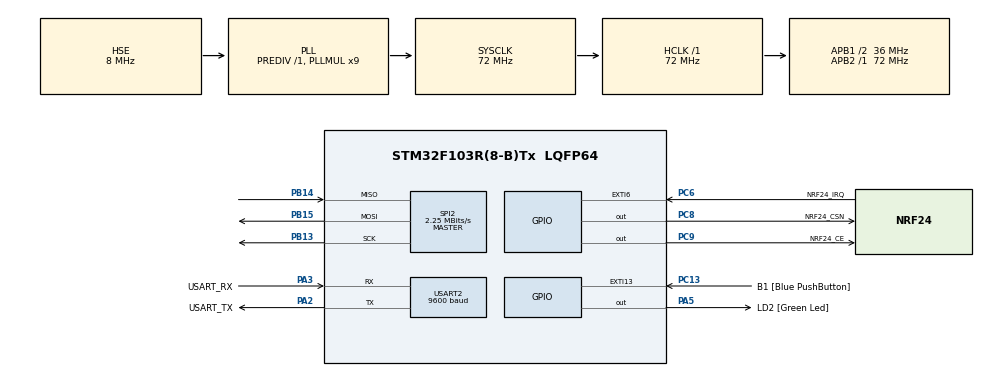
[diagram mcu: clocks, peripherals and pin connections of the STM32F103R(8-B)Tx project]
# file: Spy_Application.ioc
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Mcu.Family=STM32F1
Mcu.Name=STM32F103R(8-B)Tx
Mcu.Package=LQFP64
NVIC.EXTI15_10_IRQn=true\:0\:0\:false\:false\:true\:true\:true
NVIC.EXTI9_5_IRQn=true\:0\:0\:false\:false\:true\:true\:true
NVIC.PriorityGroup=NVIC_PRIORITYGROUP_4
PA13.GPIO_Label=TMS
PA13.Mode=Serial_Wire
PA13.Signal=SYS_JTMS-SWDIO
PA14.GPIO_Label=TCK
PA14.Mode=Serial_Wire
PA14.Signal=SYS_JTCK-SWCLK
PA2.GPIO_Label=USART_TX
PA2.GPIO_Mode=GPIO_MODE_AF_PP
PA2.GPIO_PuPd=GPIO_NOPULL
PA2.GPIO_Speed=GPIO_SPEED_FREQ_LOW
PA2.Mode=Asynchronous
PA2.Signal=USART2_TX
PA3.GPIO_Label=USART_RX
PA3.GPIO_Mode=GPIO_MODE_AF_PP
PA3.GPIO_PuPd=GPIO_NOPULL
PA3.GPIO_Speed=GPIO_SPEED_FREQ_LOW
PA3.Mode=Asynchronous
PA3.Signal=USART2_RX
PA5.GPIO_Label=LD2 [Green Led]
PA5.GPIO_ModeDefaultOutputPP=GPIO_MODE_OUTPUT_PP
PA5.GPIO_PuPd=GPIO_NOPULL
PA5.GPIO_Speed=GPIO_SPEED_FREQ_LOW
PA5.Signal=GPIO_Output
PB13.Mode=Full_Duplex_Master
PB13.Signal=SPI2_SCK
PB14.Mode=Full_Duplex_Master
PB14.Signal=SPI2_MISO
PB15.Mode=Full_Duplex_Master
PB15.Signal=SPI2_MOSI
PB3.GPIO_Label=SWO
PB3.Signal=SYS_JTDO-TRACESWO
PC13-TAMPER-RTC.GPIO_Label=B1 [Blue PushButton]
PC13-TAMPER-RTC.GPIO_PuPd=GPIO_NOPULL
PC13-TAMPER-RTC.Signal=GPXTI13
PC14-OSC32_IN.Mode=LSE-External-Oscillator
PC14-OSC32_IN.Signal=RCC_OSC32_IN
PC15-OSC32_OUT.Mode=LSE-External-Oscillator
PC15-OSC32_OUT.Signal=RCC_OSC32_OUT
PC6.GPIO_Label=NRF24_IRQ
PC6.GPIO_ModeDefaultEXTI=GPIO_MODE_IT_FALLING
PC6.GPIO_PuPd=GPIO_PULLUP
PC6.Signal=GPXTI6
PC8.GPIO_Label=NRF24_CSN
PC8.Signal=GPIO_Output
PC9.GPIO_Label=NRF24_CE
PC9.Signal=GPIO_Output
PD0-OSC_IN.Mode=HSE-External-Clock-Source
PD0-OSC_IN.Signal=RCC_OSC_IN
PD1-OSC_OUT.Mode=HSE-External-Clock-Source
PD1-OSC_OUT.Signal=RCC_OSC_OUT
ProjectManager.HeapSize=0x200
ProjectManager.StackSize=0x400
ProjectManager.TargetToolchain=STM32CubeIDE
RCC.AHBFreq_Value=72000000
RCC.APB1CLKDivider=RCC_HCLK_DIV2
RCC.APB1Freq_Value=36000000
RCC.APB1TimFreq_Value=72000000
RCC.APB2Freq_Value=72000000
RCC.APB2TimFreq_Value=72000000
RCC.HCLKFreq_Value=72000000
RCC.PLLMUL=RCC_PLL_MUL9
RCC.PLLSourceVirtual=RCC_PLLSOURCE_HSE
RCC.RTCClockSelection=RCC_RTCCLKSOURCE_LSE
RCC.SYSCLKFreq_VALUE=72000000
RCC.SYSCLKSource=RCC_SYSCLKSOURCE_PLLCLK
RCC.USBFreq_Value=72000000
SPI2.BaudRatePrescaler=SPI_BAUDRATEPRESCALER_16
SPI2.CalculateBaudRate=2.25 MBits/s
SPI2.Direction=SPI_DIRECTION_2LINES
SPI2.Mode=SPI_MODE_MASTER
SPI2.VirtualType=VM_MASTER
USART2.BaudRate=9600
USART2.VirtualMode=VM_ASYNC
board=NUCLEO-F103RB

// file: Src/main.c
/* USER CODE BEGIN Header */
/**
  ******************************************************************************
  * @file           : main.c
  * @brief          : Main program body
  ******************************************************************************
  * @attention
  *
  * <h2><center>&copy; Copyright (c) 2021 STMicroelectronics.
  * All rights reserved.</center></h2>
  *
  * This software component is licensed by ST under BSD 3-Clause license,
  * the "License"; You may not use this file except in compliance with the
  * License. You may obtain a copy of the License at:
  *                        opensource.org/licenses/BSD-3-Clause
  *
  ******************************************************************************
  */
/* USER CODE END Header */

#include "main.h"
#include "spi.h"
#include "usart.h"
#include "gpio.h"

/* USER CODE BEGIN Includes */
#include "MY_NRF24.h"
/* USER CODE END Includes */

/* USER CODE BEGIN PV */
uint8_t myRxData[1000u];
/* USER CODE END PV */

void SystemClock_Config(void);

int main(void)
{

  /* MCU Configuration--------------------------------------------------------*/

  /* Reset of all peripherals, Initializes the Flash interface and the Systick. */
  HAL_Init();

  /* Configure the system clock */
  SystemClock_Config();

  /* Initialize all configured peripherals */
  MX_GPIO_Init();
  MX_SPI2_Init();
  MX_USART2_UART_Init();
  /* USER CODE BEGIN 2 */
  NRF24_begin(NRF24_CE_GPIO_Port, NRF24_CSN_Pin, NRF24_CE_Pin, hspi2);
  NRF24_startListening();

  uint8_t data[100u];
  uint16_t Size = sprintf(data, "SPY_APPLICATION\r\n");
  HAL_UART_Transmit(&huart2, data, Size, 100u);
  /* USER CODE END 2 */

  /* Infinite loop */
  while (1)
  {

  }
}

void SystemClock_Config(void)
{
  RCC_OscInitTypeDef RCC_OscInitStruct = {0};
  RCC_ClkInitTypeDef RCC_ClkInitStruct = {0};

  /** Initializes the CPU, AHB and APB busses clocks
  */
  RCC_OscInitStruct.OscillatorType = RCC_OSCILLATORTYPE_HSE;
  RCC_OscInitStruct.HSEState = RCC_HSE_BYPASS;
  RCC_OscInitStruct.HSEPredivValue = RCC_HSE_PREDIV_DIV1;
  RCC_OscInitStruct.HSIState = RCC_HSI_ON;
  RCC_OscInitStruct.PLL.PLLState = RCC_PLL_ON;
  RCC_OscInitStruct.PLL.PLLSource = RCC_PLLSOURCE_HSE;
  RCC_OscInitStruct.PLL.PLLMUL = RCC_PLL_MUL9;
  if (HAL_RCC_OscConfig(&RCC_OscInitStruct) != HAL_OK)
  {
    Error_Handler();
  }
  /** Initializes the CPU, AHB and APB busses clocks
  */
  RCC_ClkInitStruct.ClockType = RCC_CLOCKTYPE_HCLK|RCC_CLOCKTYPE_SYSCLK
                              |RCC_CLOCKTYPE_PCLK1|RCC_CLOCKTYPE_PCLK2;
  RCC_ClkInitStruct.SYSCLKSource = RCC_SYSCLKSOURCE_PLLCLK;
  RCC_ClkInitStruct.AHBCLKDivider = RCC_SYSCLK_DIV1;
  RCC_ClkInitStruct.APB1CLKDivider = RCC_HCLK_DIV2;
  RCC_ClkInitStruct.APB2CLKDivider = RCC_HCLK_DIV1;

  if (HAL_RCC_ClockConfig(&RCC_ClkInitStruct, FLASH_LATENCY_2) != HAL_OK)
  {
    Error_Handler();
  }
}

/* USER CODE BEGIN 4 */
void HAL_GPIO_EXTI_Callback(uint16_t GPIO_Pin)
{
  if(GPIO_Pin == GPIO_PIN_6)
  {
    // New data arrived in the RX buffer

    // Read the data from RX FIFO
    NRF24_read(myRxData, 32);

    if(myRxData[0u] != (255u ^ 33u))
    {
      HAL_UART_Transmit(&huart2, (uint8_t*)myRxData, 32u, 100u);
    }

    // Reset RX_DR flag in STATUS register
    NRF24_write_register(REG_STATUS,_BV(BIT_RX_DR) );
  }
}
/* USER CODE END 4 */

void Error_Handler(void)
{
}

/************************ (C) COPYRIGHT STMicroelectronics *****END OF FILE****/
